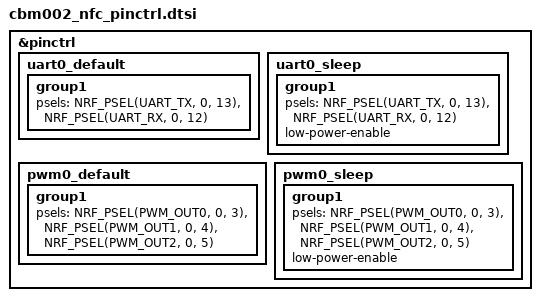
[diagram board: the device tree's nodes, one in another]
&pinctrl {
	uart0_default: uart0_default {
		group1 {
			psels = <NRF_PSEL(UART_TX, 0, 13)>,
				<NRF_PSEL(UART_RX, 0, 12)>;
				// <NRF_PSEL(UART_RTS, 0, 6)>, // unused
				// <NRF_PSEL(UART_CTS, 0, 7)>; // unused
		};
	};

	uart0_sleep: uart0_sleep {
		group1 {
			psels = <NRF_PSEL(UART_TX, 0, 13)>,
				<NRF_PSEL(UART_RX, 0, 12)>;
				// <NRF_PSEL(UART_RTS, 0, 6)>, // unused
				// <NRF_PSEL(UART_CTS, 0, 7)>; // unused
			low-power-enable;
		};
	};

	pwm0_default: pwm0_default {
		group1 {
			psels = <NRF_PSEL(PWM_OUT0, 0, 3)>, 
					<NRF_PSEL(PWM_OUT1, 0, 4)>,
					<NRF_PSEL(PWM_OUT2, 0, 5)>;
		};
	};

	pwm0_sleep: pwm0_sleep {
		group1 {
			psels = <NRF_PSEL(PWM_OUT0, 0, 3)>,
					<NRF_PSEL(PWM_OUT1, 0, 4)>,
					<NRF_PSEL(PWM_OUT2, 0, 5)>;
			low-power-enable;
		};
	};

};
